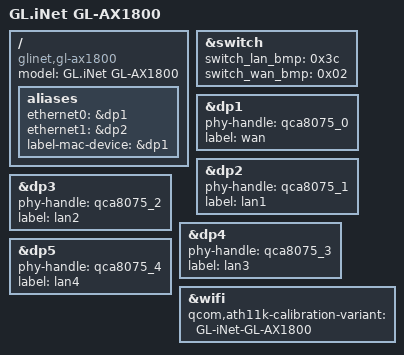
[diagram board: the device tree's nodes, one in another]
// SPDX-License-Identifier: GPL-2.0-or-later OR MIT

/dts-v1/;

#include "ipq6000-glinet.dtsi"

/ {
	model = "GL.iNet GL-AX1800";
	compatible = "glinet,gl-ax1800", "qcom,ipq6018";

	aliases {
		ethernet0 = &dp1;
		ethernet1 = &dp2;
		label-mac-device = &dp1;
	};
};

&switch {
	switch_lan_bmp = <0x3c>; /* lan port bitmap */
	switch_wan_bmp = <0x02>; /* wan port bitmap */
};

&dp1 {
	status = "okay";
	phy-handle = <&qca8075_0>;
	label = "wan";
};

&dp2 {
	status = "okay";
	phy-handle = <&qca8075_1>;
	label = "lan1";
};

&dp3 {
	status = "okay";
	phy-handle = <&qca8075_2>;
	label = "lan2";
};

&dp4 {
	status = "okay";
	phy-handle = <&qca8075_3>;
	label = "lan3";
};

&dp5 {
	status = "okay";
	phy-handle = <&qca8075_4>;
	label = "lan4";
};

&wifi {
	qcom,ath11k-calibration-variant = "GL-iNet-GL-AX1800";
};
